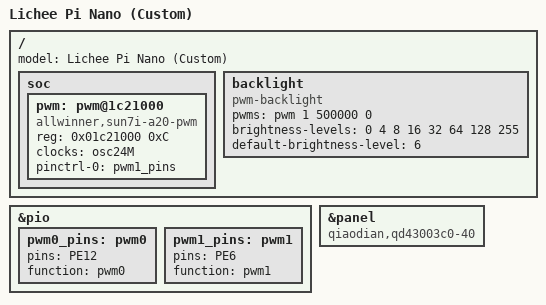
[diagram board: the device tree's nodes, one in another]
// SPDX-License-Identifier: (GPL-2.0+ OR X11)
// based on https://github.com/Lichee-Pi/linux/blob/nano-5.2-flash/arch/arm/boot/dts/suniv-f1c100s-licheepi-nano.dts on 2021-08
/*
 * Copyright 2018 Icenowy Zheng <icenowy@aosc.io>
 */

/dts-v1/;
#include "suniv-f1c100s-licheepi-nano.dts"

/* @todo move to dtsi */
&pio {
	pwm0_pins: pwm0 {
		pins = "PE12";
		function = "pwm0";
	};
	pwm1_pins: pwm1 {
		pins = "PE6";
		function = "pwm1";
	};
};

/ {
	model = "Lichee Pi Nano (Custom)";

	/* @todo move to dtsi */
	soc {
		pwm: pwm@1c21000 {
			compatible = "allwinner,sun7i-a20-pwm";
			reg = <0x01c21000 0xC>;
			clocks = <&osc24M>;
			#pwm-cells = <3>;
			status = "disabled";
		};
	};

	backlight {
		compatible = "pwm-backlight";
		pwms = <&pwm 1 500000 0>;
		brightness-levels = <0 4 8 16 32 64 128 255>;
		default-brightness-level = <6>;
	};
};

&panel {
	// override default resolution (800x480) with smaller resolution: 480x272
	compatible = "qiaodian,qd43003c0-40", "simple-panel";

	// remove default GPIO property @todo improve
	/delete-property/ enable-gpios;
};

&pwm {
	pinctrl-names = "default";
	pinctrl-0 = <&pwm1_pins>;
	status = "okay";
};

/*
&lradc {
	// keymap for low-resolution ADC input driver
	// (pulling voltage down to different levels 0V-2V on LRADC pin causes this to emit different
	// keyboard codes - pull pin back up to 3.3V when button is off)
	button-200 {
		label = "Volume Up";
		linux,code = <KEY_VOLUMEUP>;
		channel = <0>;
		voltage = <200000>;
	};

	button-400 {
		label = "Volume Down";
		linux,code = <KEY_VOLUMEDOWN>;
		channel = <0>;
		voltage = <400000>;
	};

	button-600 {
		label = "Select";
		linux,code = <KEY_SELECT>;
		channel = <0>;
		voltage = <600000>;
	};

	button-800 {
		label = "Start";
		linux,code = <KEY_OK>;
		channel = <0>;
		voltage = <800000>;
	};
};
*/

/*
&flash {
	// hard-coded partition table for booting from Flash
	partitions {
		compatible = "fixed-partitions";
		#address-cells = <1>;
		#size-cells = <1>;

		partition@0 {
			label = "u-boot";
			reg = <0x000000 0x100000>;
			read-only;
		};

		partition@100000 {
			label = "dtb";
			reg = <0x100000 0x10000>;
			read-only;
		};

		partition@110000 {
			label = "kernel";
			reg = <0x110000 0x400000>;
			read-only;
		};

		partition@520000 {
			label = "rootfs";
			reg = <0x510000 0xAF0000>;
		};
	};
};
*/
